VERSION ""

NS_ :

BS_:

BU_:
VAL_TABLE_ Service_Brake_State_Table 3 "Service_brake_state_available" 2 "Service_brake_state_engaged" 1 "Service_brake_state_disengaged" ;
VAL_TABLE_ Autonomous_Mission_Table 6 "AMI_state_autocross" 5 "AMI_state_inspection" 4 "AMI_state_braketest" 3 "AMI_state_trackdrive" 2 "AMI_state_skidpad" 1 "AMI_state_acceleration" ;
VAL_TABLE_ EBS_State_Table 3 "EBS_state_activated" 2 "EBS_state_armed" 1 "EBS_state_unavailable" ;
VAL_TABLE_ Autonomous_State_Table 6 "AS_state_manual" 5 "AS_state_finish" 4 "AS_state_emergency_brake" 3 "AS_state_driving" 2 "AS_state_ready" 1 "AS_state_off" ;

BO_ 376 BMS_CONTROL: 3 Vector__XXX
 SG_ hv_req : 0|8@1+ (1,0) [0|255] "" Vector__XXX
 SG_ control_seq : 8|8@1+ (1,0) [0|255] "" Vector__XXX

BO_ 56 BMS_Master_Req: 2 Vector__XXX
 SG_ master_req : 0|8@1+ (1,0) [0|255] "" Vector__XXX

BO_ 1280 AS_Debug: 1 Vector__XXX

BO_ 1298 AS_Main: 5 Vector__XXX

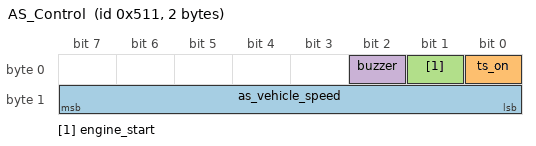
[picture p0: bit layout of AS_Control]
BO_ 1297 AS_Control: 2 Vector__XXX
 SG_ as_vehicle_speed : 8|8@1- (1,0) [0|0] "" Vector__XXX
 SG_ ts_on : 0|1@1+ (1,0) [0|1] "" Vector__XXX
 SG_ engine_start : 1|1@1+ (1,0) [0|1] "" Vector__XXX
 SG_ buzzer : 2|1@1+ (1,0) [0|1] "" Vector__XXX
